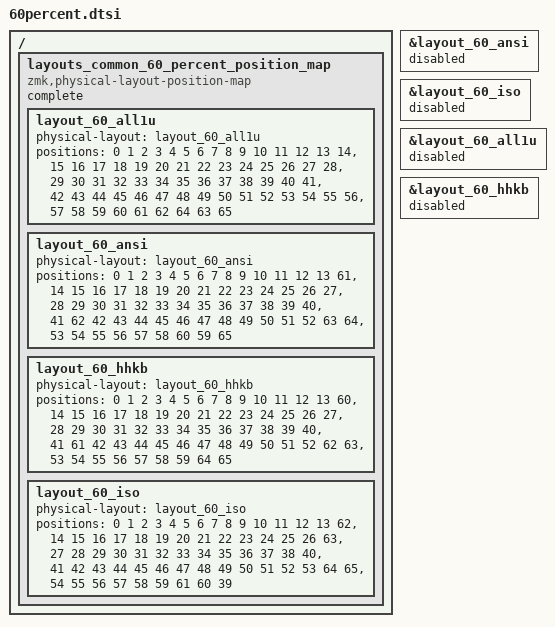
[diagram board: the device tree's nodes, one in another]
#include <layouts/common/60percent/ansi.dtsi>
#include <layouts/common/60percent/iso.dtsi>
#include <layouts/common/60percent/all1u.dtsi>
#include <layouts/common/60percent/hhkb.dtsi>

&layout_60_ansi {
    status = "disabled";
};

&layout_60_iso {
    status = "disabled";
};

&layout_60_all1u {
    status = "disabled";
};

&layout_60_hhkb {
    status = "disabled";
};

/ {
    layouts_common_60_percent_position_map: layouts_common_60_percent_position_map {
        compatible = "zmk,physical-layout-position-map";

        complete;

        layout_60_all1u {
            physical-layout = <&layout_60_all1u>;
            positions
                = < 0  1  2  3  4  5  6  7  8  9 10 11 12 13 14>
                , <15 16 17 18 19 20 21 22 23 24 25 26 27 28>
                , <29 30 31 32 33 34 35 36 37 38 39 40 41>
                , <42 43 44 45 46 47 48 49 50 51 52 53 54 55 56>
                , <57 58 59 60 61 62 64 63 65>
                ;
        };

        layout_60_ansi {
            physical-layout = <&layout_60_ansi>;
            positions
                = < 0  1  2  3  4  5  6  7  8  9 10 11 12 13 61>
                , <14 15 16 17 18 19 20 21 22 23 24 25 26 27>
                , <28 29 30 31 32 33 34 35 36 37 38 39 40>
                , <41 62 42 43 44 45 46 47 48 49 50 51 52 63 64>
                , <53 54 55 56 57 58 60 59 65>
                ;
        };

        layout_60_hhkb {
            physical-layout = <&layout_60_hhkb>;
            positions
                = < 0  1  2  3  4  5  6  7  8  9 10 11 12 13 60>
                , <14 15 16 17 18 19 20 21 22 23 24 25 26 27>
                , <28 29 30 31 32 33 34 35 36 37 38 39 40>
                , <41 61 42 43 44 45 46 47 48 49 50 51 52 62 63>
                , <53 54 55 56 57 58 59 64 65>
                ;
        };

        layout_60_iso {
            physical-layout = <&layout_60_iso>;
            positions
                = < 0  1  2  3  4  5  6  7  8  9 10 11 12 13 62>
                , <14 15 16 17 18 19 20 21 22 23 24 25 26 63>
                , <27 28 29 30 31 32 33 34 35 36 37 38 40>
                , <41 42 43 44 45 46 47 48 49 50 51 52 53 64 65>
                , <54 55 56 57 58 59 61 60 39>
                ;
        };
    };
};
